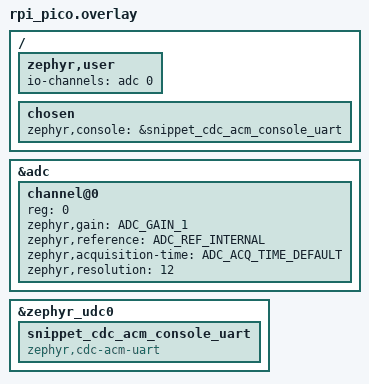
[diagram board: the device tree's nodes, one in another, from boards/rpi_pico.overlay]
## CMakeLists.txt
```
# Copyright (c) 2021-2022 TiaC Systems
# SPDX-License-Identifier: Apache-2.0

cmake_minimum_required(VERSION 3.20.0)

# Standard Bridle application boilerplate, includes Zephyr.
find_package(Bridle REQUIRED HINTS $ENV{BRIDLE_BASE})
project("picoclock" VERSION 1.0)
include_directories(inc/)
target_sources(app PRIVATE src/main.c src/display.c src/temp.c src/led.c src/rtc.c src/temp.c src/menu.c src/io.c)
```

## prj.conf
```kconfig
CONFIG_GPIO=y
CONFIG_DISPLAY=y
CONFIG_HEAP_MEM_POOL_SIZE=16384
CONFIG_LOG=y
CONFIG_RTC=y
CONFIG_RTC_UPDATE=y
CONFIG_RTC_ALARM=y
CONFIG_I2C=y
CONFIG_SENSOR=y
CONFIG_ADC=y
```

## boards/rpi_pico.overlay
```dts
/*
 * SPDX-License-Identifier: Apache-2.0
 *
 * Copyright (c) 2022 TOKITA Hiroshi <tokita.hiroshi@fujitsu.com>
 */

/ {
	zephyr,user {
		io-channels = <&adc 0>;
	};
	chosen {
			zephyr,console = &snippet_cdc_acm_console_uart;
		};
	        
		
};

&adc {
	#address-cells = <1>;
	#size-cells = <0>;

	channel@0 {
		reg = <0>;
		zephyr,gain = "ADC_GAIN_1";
		zephyr,reference = "ADC_REF_INTERNAL";
		zephyr,acquisition-time = <ADC_ACQ_TIME_DEFAULT>;
		zephyr,resolution = <12>;
	};
};

/*
 * Copyright (c) 2023 TiaC Systems
 * SPDX-License-Identifier: Apache-2.0
 */



&zephyr_udc0 {
	snippet_cdc_acm_console_uart: snippet_cdc_acm_console_uart {
		compatible = "zephyr,cdc-acm-uart";
	};
};
```

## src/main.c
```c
#include <string.h>
#include <zephyr/kernel.h>
#include <zephyr/drivers/display.h>
#include <zephyr/device.h>
#include <zephyr/drivers/rtc.h>
#include <zephyr/drivers/sensor.h>
#include <zephyr/drivers/gpio.h>
#include <zephyr/sys/util.h>
#include <zephyr/drivers/adc.h>

#include "def.h"
#include "display.h"
#include "temp.h"
#include "led.h"
#include "menu.h"
#include "rtc.h"
#include "temp.h"
#include "io.h"

static struct gpio_dt_spec button = GPIO_DT_SPEC_GET(DT_ALIAS(sw0), gpios);
static struct gpio_dt_spec button2 = GPIO_DT_SPEC_GET(DT_ALIAS(sw1), gpios);
static struct gpio_dt_spec button3 = GPIO_DT_SPEC_GET(DT_ALIAS(sw2), gpios);



struct display_capabilities caps;



//basically copied example from zephyr/samples/drivers/adc
//with the rpi_pico.overlay thing because nothing else worked
//in boards/rpi_pico.overlay

const struct adc_dt_spec adc_channel0 = ADC_DT_SPEC_GET(DT_PATH(zephyr_user));

const struct device *dev = DEVICE_DT_GET(DT_CHOSEN(zephyr_display));

const struct device *rtc = DEVICE_DT_GET(DT_NODELABEL(clock_rtc));

const struct device *devtemp = DEVICE_DT_GET(DT_NODELABEL(clock_dts));


//Flags
//from menu.h global bool variables, menu.c sets those variables; main.c and menu.c uses them

int main() {


    gpio_pin_configure_dt(&button, GPIO_INPUT);
    gpio_pin_configure_dt(&button2, GPIO_INPUT);
    gpio_pin_configure_dt(&button3, GPIO_INPUT);
    
    struct rtc_time time;/* = {
        .tm_sec = 0,            //sec
        .tm_min = 47,           //minute
        .tm_hour = 9,          //hour
        .tm_mday = 15,          //day of month
        .tm_mon = 2,            //month
        .tm_year = 2024,        //year
        .tm_wday = 6,           //weekday
        
    };
  
    
    rtc_set_time(rtc,&time);*/
    rtc_get_time(rtc, &time);
    printf("year rtc from main.c: %d\n", time.tm_year);


    display_get_capabilities(dev, &caps);
    display_set_pixel_format(dev, PIXEL_FORMAT_MONO01 );
    
   
    printf("x res: %d\ny res: %d\n",caps.x_resolution, caps.y_resolution);

    clearDisplay(dev);

    //writing stuff
    
    displayChar(dev, POS1, POSY,'0');
    displayChar(dev, POS2, POSY,'1');
    displayChar(dev, POSCOL, POSY,':');
    displayChar(dev, POS3, POSY,2);
    displayChar(dev, POS4, POSY,3);    
    
    int hour = 0;
    int minute = 0;
    int day = 0; 
    int currentPosHr = POS1;
    int currentPosMin = POS3;
    
    clearDisplay(dev);
    
    int prevHr = -1;
    int prevMin = -1;
    int prevDay = -1;
    int returnSwitchTemp = -1;
    int returnSwitchMenu = -1;
    int returnTimeAndDay = -1;
    uint8_t val = 12;
    uint8_t bcd = bin2bcd(val);

/*
    bcd:
    dec to bin: 
    12
    0000 1100
    bcd:
dec: 1    2
    0001 0010

*/

    uint8_t mask = 0b00001111;  
    uint8_t secondDigit = ((bcd >> 0) & mask) + 0x30;    //mask the first ,4bit
    uint8_t firstDigit = ((bcd >> 4) & mask) + 0x30;  //mask the second 4bit and add value to go to the 0-9 values in the ascii table
    

    printf("first digit ascii num: %x char: %c\n", firstDigit,(char)firstDigit);
    printf("second digit ascii num: %x char: %c\n", secondDigit,(char)secondDigit);

    //turn on by default
    //bool toggleAutolight = true; 
    
    while(true){
        //printf("H: %d  M: %d  S: %d  \n",time.tm_hour, time.tm_min, time.tm_sec);
        
        //because of blinkChar() you'll have to wait until this if condition is checked in the while loop
        //just a simple example/test for the button; possible fix with "async interrupt handlers (?)"
        //https://docs.zephyrproject.org/latest/kernel/services/interrupts.html
        //for now press the button longer a bit to trigger the if statements in main() and switchToTemp() 

        //buttons
        int val = gpio_pin_get_dt(&button);
        int val2 = gpio_pin_get_dt(&button2);
        int val3 = gpio_pin_get_dt(&button3);
        //printf("buttonval: %d\n", val);
        if(val != 0){
            
            returnSwitchTemp = switchToTemp(dev,devtemp); //switch to the temperature view and stay there until button is pressed again
            
        }
        if(val2 != 0){
            //scrollText(dev,':');


            //set time and date
            
            returnTimeAndDay = setTimeAndDay(dev,rtc);

        }

        
        if(val3 != 0){
            /*if(toggleAutolight == true){
                toggleAutolight = false;
                setLED(dev, 10, 0);
            }
            else{
                toggleAutolight = true;
                setLED(dev, 10, 1);
                
            }*/
            returnSwitchMenu = switchToMenu(dev);
            

        }
        

        if(f_autolight){
            setLED(dev, 12, 1); //if you change to temp display or clockset display the led goes of because clearLEDs() is called in those functions this turns on the hole time while toggleAutolight is true

            updateAutolight(dev, adc_channel0);
            
        }
        else{
            setLED(dev, 12, 0);
        }
        
        
        if(returnSwitchTemp == 0){
            //if returned from switchToTemp() update/set hours and minutes
            prevHr = -1;
            prevMin = -1; //set to default to simulate "restart"
            prevDay = -1;
            returnSwitchTemp = -1; //set it to -1 or any value to not trigger this statement again
            printf("display reset!\n");
        }
        if(returnSwitchMenu == 0){
            prevHr = -1;
            prevMin = -1;
            prevDay = -1;
            returnSwitchMenu = -1;
            printf("display reset!\n");

        }
        if(returnTimeAndDay == 0){
            prevHr = -1;
            prevMin = -1;
            prevDay = -1;
            returnTimeAndDay = -1;
            printf("display reset!\n");

        }

        
        rtc_get_time(rtc, &time);
        if(f_twelveHourClock == true){
            //activate am/pm func (just turn on/off leds for )
            setLED(dev, 9, 1);
            //maybe
            // https://stackoverflow.com/questions/63976824/how-to-convert-hour-number-from-24h-to-12h-format-without-any-conditional-operat
            if(time.tm_hour < 12){ //from 0-12 in 24h format
                //in the AMs
                setLED(dev, 8, 1); //turn on AM led
                setLED(dev, 9, 0); //turn off PM led

                int hourFormatted = (time.tm_hour % 12); // limit to 12
                if(hourFormatted == 0){
                    hourFormatted = 12; //take care of 0s in 24h format, they dont exist in 12h format
                }
                //printf("hour in 12h format: %d\nnormal hour: %d\n", hourFormatted, time.tm_hour);
                hour = hourFormatted;       
                

                
            }
            if(time.tm_hour > 11){ //from 12-24 in 24h format 
                //in the PMs
                
                setLED(dev, 8, 0); //turn off AM led
                setLED(dev, 9, 1); //turn on PM led
                int hourFormatted = (time.tm_hour % 12); // limit to 12
                if(hourFormatted == 0){ //take care of 0s in 24h format, they dont exist in 12h format
                    hourFormatted = 12;
                }
                //printf("hour in 12h format: %d\nnormal hour: %d\n", hourFormatted, time.tm_hour);
                hour = hourFormatted; //set the main hour variable to the formatted 12h version
                
            }
            
        }
        else if(f_twelveHourClock == false){
            
            setLED(dev, 8, 0);
            setLED(dev, 9, 0);
            hour = time.tm_hour; //dont set main hour variable to the formatted 12h version, keep it as is
        }
        
        minute = time.tm_min; 
        day = time.tm_wday;
        
            

        
        if(hour < 10 && (hour != prevHr)){
            clearChar(dev,currentPosHr,POSY); //clear previous char
            displayChar(dev, currentPosHr, POSY, '0'); //set it to 0 so it doesnt look empty
            currentPosHr = POS2; //update location 
            clearChar(dev,currentPosHr,POSY);
            displayChar(dev, currentPosHr, POSY, hour + '0'); //converting it to a char so it looks up the ascii table 
            prevHr = hour;
            currentPosHr = POS1;

        }
//seperate 2digit int into 2 seperate ints via bcd 
        else if(hour > 9 && (hour != prevHr)){

            uint8_t bcd = bin2bcd(hour);

            uint8_t mask = 0b00001111;
    
            uint8_t secondDigit = ((bcd >> 0) & mask) + 0x30;    //mask the first 4bit
            uint8_t firstDigit = ((bcd >> 4) & mask) + 0x30;  //mask the second 4bit and add value to go to the 0-9 values in the ascii table
            currentPosHr = POS1;
            
            clearChar(dev,POS1,POSY);
            displayChar(dev, POS1, POSY, firstDigit);
            clearChar(dev,POS2, POSY);
            displayChar(dev, POS2, POSY, secondDigit);
            prevHr = hour;

        }

        
        
        if(minute < 10 && (minute != prevMin)){
            clearChar(dev, currentPosMin,POSY); //clear previous char
            displayChar(dev, currentPosMin, POSY, '0'); //set it to 0 so it doesnt look empty


            currentPosMin = POS4; //update location 
            clearChar(dev,currentPosMin,POSY);
            displayChar(dev, currentPosMin, POSY, minute + '0');
            prevMin = minute;
            currentPosMin = POS3;

        }
        else if(minute > 9 && (minute != prevMin)){

            uint8_t bcd = bin2bcd(minute);

            uint8_t mask = 0b00001111;
    
            uint8_t secondDigit = ((bcd >> 0) & mask) + 0x30;    //mask the first 4bit
            uint8_t firstDigit = ((bcd >> 4) & mask) + 0x30;  //mask the second 4bit and add value to go to the 0-9 values in the ascii table            
            currentPosMin = POS3;
            
            clearChar(dev,POS3,POSY);
            displayChar(dev, POS3, POSY, firstDigit);
            clearChar(dev,POS4, POSY);
            displayChar(dev, POS4, POSY, secondDigit);    
            prevMin = minute;
        
        }

        if(day != prevDay){
            updateDay(rtc);
            printf("updating (prev) day   %d %d\n",day, prevDay);
            prevDay = day;
            printf("updating day   %d %d\n",day, prevDay);
        }

        blinkChar(dev, POSCOL, POSY, ':');
        
        /* TEST FOR FLICKERING 
        //flickers everytime on rtc_get_time call
        */
        
        /*while(true){
            rtc_get_time(rtc, &time);
 
        }*/

    }    
    

    printf("Done.\n");
    return 0;
}
```

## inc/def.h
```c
#ifndef DEF_H
#define DEF_H
// defines/constants 

//defines for main positions on the led matrix
#define POS1        0
#define POS2        5
#define POSCOL      9
#define POS3       13
#define POS4       18
#define POSY        0


#endif
```

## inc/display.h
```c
#ifndef DISPLAY_H
#define DISPLAY_H

#include <zephyr/device.h>
// display specific functions 
int displayChar(const struct device *dev, int x, int y, char c);
int clearChar(const struct device *dev, int index, int y);
int clearDisplay(const struct device *dev);
void blinkChar(const struct device *dev, int x, int y, char c);
int dimmDisplay(const struct device *dev, uint8_t brightness);


#endif
```

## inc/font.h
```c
#ifndef FONT_H
#define FONT_H

//FONT[1][2]: 
//      1 = total elements
//      2 = lines inside elements
const unsigned char FONT[128][7] = {
    //values in binary because easier to read
    //ascii values, empty if none used
    { /* ascii_0 */ },
    { /* ascii_1 */ },
    { /* ascii_2 */ },
    { /* ascii_3 */ },
    { /* ascii_4 */ },
    { /* ascii_5 */ },
    { /* ascii_6 */ },
    { /* ascii_7 */ },
    { /* ascii_8 */ },
    { /* ascii_9 */ },
    { /* ascii_10 */ },
    { /* ascii_11 */ },
    { /* ascii_12 */ },
    { /* ascii_13 */ },
    { /* ascii_14 */ },
    { /* ascii_15 */ },
    { /* ascii_16 */ },
    { /* ascii_17 */ },
    { /* ascii_18 */ },
    { /* ascii_19 */ },
    { /* ascii_20 */ },
    { /* ascii_21 */ },
    { /* ascii_22 */ },
    { /* ascii_23 */ },
    { /* ascii_24 */ },
    { /* ascii_25 */ },
    { /* ascii_26 */ },
    { /* ascii_27 */ },
    { /* ascii_28 */ },
    { /* ascii_29 */ },
    { /* ascii_30 */ },
    { /* ascii_31 */ },
    { /* ascii_32 */ },
    { /* ascii_33 */ },
    { /* ascii_34 */ },
    { /* ascii_35 */ },
    { /* ascii_36 */ },
    { /* ascii_37 */ },
    { /* ascii_38 */ },
    { /* ascii_39 */ },
    { /* ascii_40 */ },
    { /* ascii_41 */ },
    { /* ascii_42 */ },
    { /* ascii_43 */ },
    { /* ascii_44 */ },
    { /* ascii_45 */ },
    { /* acsii_46, hex:  0x2e, char: '.' */ 
        
        0b00000000,
        0b00000000,
        0b00000000,
        0b00000000,
        0b00000000,
        0b00000110,
        0b00000110
    },
    { /* ascii_47 */ },
    { /* acsii_48, hex: 0x30, char: '0' */ 
        0b00000110,
        0b00001001,
        0b00001001,
        0b00001001,
        0b00001001,
        0b00001001,
        0b00000110
    },
    { /* acsii_49, hex: 0x31, char: '1' */ 
        0b00000010,
        0b00000110,
        0b00001010,
        0b00000010,
        0b00000010,
        0b00000010,
        0b00000010
    },
    { /* acsii_50, hex: 0x32, char: '2' */ 
        0b00000110,
        0b00001001,
        0b00000001,
        0b00000010,
        0b00000100,
        0b00001000,
        0b00001111
    },
    { /* acsii_51, hex: 0x33, char: '3' */
        0b00000110,
        0b00001001,
        0b00000001,
        0b00000110,
        0b00000001,
        0b00001001,
        0b00000110
    },
    { /* acsii_52, hex: 0x34, char: '4' */ 
        0b00000001,
        0b00000011,
        0b00000101,
        0b00001001,
        0b00001111,
        0b00000001,
        0b00000001
    },
    { /* acsii_53, hex: 0x35, char: '5' */ 
        0b00001111,
        0b00001000,
        0b00001110,
        0b00000001,
        0b00000001,
        0b00001001,
        0b00000110
    },
    { /* acsii_54, hex: 0x36, char: '6' */ 
        0b00000010,
        0b00000100,
        0b00001000,
        0b00001110,
        0b00001001,
        0b00001001,
        0b00000110
    },
    { /* acsii_55, hex: 0x37, char: '7' */ 
        0b00001111,
        0b00001001,
        0b00000001,
        0b00000010,
        0b00000010,
        0b00000010,
        0b00000010
        
    },
    { /* acsii_56, hex: 0x38, char: '8' */ 
        0b00000110,
        0b00001001,
        0b00001001,
        0b00000110,
        0b00001001,
        0b00001001,
        0b00000110
    },
    { /* acsii_57, hex: 0x39, char: '9' */ 
        0b00000110,
        0b00001001,
        0b00001001,
        0b00000111,
        0b00000001,
        0b00000010,
        0b00000100
    },
    {  /* acsii_58, hex: 0x3a, char: ':' */ 
        0b00000000,         //........
        0b00000110,         //.....11.
        0b00000110,         //.....11.
        0b00000000,         //........
        0b00000110,         //.....11.
        0b00000110,         //.....11.
        0b00000000          //........
    },
    { /* ascii_59 */ },
    { /* ascii_60 */ },
    { /* ascii_61 */ },
    { /* ascii_62 */ },
    { /* ascii_63 */ },
    { /* ascii_64 */ },
    { /* acsii_65, hex: 0x41, char: 'A' */
        0b00000110,         //.....11.
        0b00001001,         //....1..1
        0b00001001,         //....1..1
        0b00001111,         //....1111
        0b00001001,         //....1..1
        0b00001001,         //....1..1
        0b00001001 
    },
    { /* acsii_66, hex: 0x42, char: 'B' */ 
        0b00001110,       //....111.
        0b00001001,       //....1..1
        0b00001001,       //....1..1
        0b00001110,       //....111.
        0b00001001,       //....1..1
        0b00001001,       //....1..1
        0b00001110        //....111. 
    },
    { /* acsii_67, hex: 0x43, char: 'C' */ 
        0b00000110,       //.....11.
        0b00001001,       //....1..1
        0b00001000,       //....1...
        0b00001000,       //....1...
        0b00001000,       //....1...
        0b00001001,       //....1..1
        0b00000110        //.....11. 
    },
    { /* acsii_68, hex: 0x44, char: 'D' */ 
        0b00001110,     //....111.
        0b00001001,     //....1..1
        0b00001001,     //....1..1
        0b00001001,     //....1..1
        0b00001001,     //....1..1
        0b00001001,     //....1..1
        0b00001110      //....111. 
    },
    { /* acsii_69, hex: 0x45, char: 'E' */ 
        0b00001111,     //....1111
        0b00001000,     //....1...
        0b00001000,     //....1...
        0b00001111,     //....1111
        0b00001000,     //....1...
        0b00001000,     //....1...
        0b00001111      //....1111
    },
    { /* acsii_70, hex: 0x46, char: 'F' */ 
        0b00001111,     //....1111
        0b00001000,     //....1...
        0b00001000,     //....1...
        0b00001111,     //....1111
        0b00001000,     //....1...
        0b00001000,     //....1...
        0b00001000      //....1... 
    },
    { /* ascii_71 */ },
    { /* ascii_72 */ },
    { /* ascii_73 */ },
    { /* ascii_74 */ },
    { /* ascii_75 */ },
    { /* ascii_76, hex: 0x4c, char: L */ 
        0b00001000,
        0b00001000,
        0b00001000,
        0b00001000,
        0b00001000,
        0b00001000,
        0b00001111
    },
    { /* ascii_77 */ },
    { /* ascii_78, hex: 0x4e, char: N */ 
        0b00001001,
        0b00001001,
        0b00001101,
        0b00001011,
        0b00001001,
        0b00001001,
        0b00001001
    },
    { /* ascii_79, hex: 0x4f, char: O */ 
        0b00000110,
        0b00001001,
        0b00001001,
        0b00001001,
        0b00001001,
        0b00001001,
        0b00000110
    },
    { /* ascii_80 */ },
    { /* ascii_81 */ },
    { /* ascii_82 */ },
    { /* ascii_83 */ },
    { /* ascii_84 */ },
    { /* ascii_85 */ },
    { /* ascii_86 */ },
    { /* ascii_87 */ },
    { /* ascii_88 */ },
    { /* ascii_89 */ },
    { /* ascii_90 */ },
    { /* ascii_91 */ },
    { /* ascii_92 */ },
    { /* ascii_93 */ },
    { /* ascii_94 */ },
    { /* ascii_95 */ },
    { /* ascii_96 */ },
    { /* ascii_97 */ },
    { /* ascii_98 */ },
    { /* ascii_99 */ },
    { /* ascii_100 */ },
    { /* ascii_101 */ },
    { /* ascii_102 */ },
    { /* ascii_103 */ },
    { /* ascii_104 */ },
    { /* ascii_105 */ },
    { /* ascii_106 */ },
    { /* ascii_107 */ },
    { /* ascii_108 */ },
    { /* ascii_109 */ },
    { /* ascii_110 */ },
    { /* ascii_111 */ },
    { /* ascii_112 */ },
    { /* ascii_113 */ },
    { /* ascii_114 */ },
    { /* ascii_115 */ },
    { /* ascii_116 */ },
    { /* ascii_117 */ },
    { /* ascii_118 */ },
    { /* ascii_119 */ },
    { /* ascii_120 */ },
    { /* ascii_121 */ },
    { /* ascii_122 */ },
    { /* ascii_123 */ },
    { /* ascii_124 */ },
    { /* ascii_125 */ },
    { /* ascii_126 */ },
    { /* ascii_127 */ }
    
};
#endif
```

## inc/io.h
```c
#ifndef IO_H
#define IO_H
#include <zephyr/device.h>
#include <zephyr/drivers/adc.h>
//functions for I/O on the board (LDR, Buzzer etc...)
void updateAutolight(const struct device *dev, const struct adc_dt_spec adc);

#endif
```

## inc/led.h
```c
#ifndef LED_H
#define LED_H
#include <zephyr/device.h>
//functions for status leds


void setLED(const struct device *dev, int number, int state);
void clearLEDs (const struct device *dev);


#endif
```

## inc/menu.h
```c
#ifndef MENU_H
#define MENU_H
#include <zephyr/device.h>
#include <stdbool.h>
//functions that change the whole screen aka switch to specified menus
int switchToMenu(const struct device *dev);
int switchToTemp(const struct device *display_device, const struct device *temp_device);
int switchToDate(const struct device *dev, const struct device *rtc);


//flags
//Flags
extern bool f_autolight;
extern bool f_twelveHourClock;

#endif
```

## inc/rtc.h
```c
#ifndef RTC_H
#define RTC_H
#include <zephyr/device.h>
//rtc functions 

void updateDay(const struct device *rtc);

int setTimeAndDay(const struct device *dev, const struct device *rtc);

#endif
```

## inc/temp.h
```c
#ifndef TEMP_H
#define TEMP_H
#include <zephyr/device.h>

//functions for temp readings

void updateTemp(const struct device *dev);



#endif
```

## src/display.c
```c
#include <stdio.h>
#include <zephyr/device.h>
#include <zephyr/drivers/display.h>
#include <zephyr/kernel.h>
#include <string.h>

#include "display.h"
#include "font.h"

int clearChar(const struct device *dev, int index, int y){
    uint8_t charbuf[7] = { };
    memset(charbuf, 0b00000000, sizeof(charbuf));
    struct display_buffer_descriptor char_buf_desc = {
        .buf_size = sizeof(charbuf),
        .width = 4,
        .height = 7,
        .pitch = 4,
    };
    int ret = display_write(dev, index, y, &char_buf_desc, charbuf);
    if(ret != 0){
        printf("display_write failed\n");
        
        return -1;
    }
    else{
        return 0;
    }
    
}

int clearDisplay(const struct device *dev){

    int x = 22;
    int y = 7;

    uint8_t dispbuf[22] = { };

    struct display_buffer_descriptor disp_buf_desc = {

        .buf_size = sizeof(dispbuf),
        .width = x,
        .height = y,
        .pitch = x,
    };
    memset(dispbuf, 0b00000000, sizeof(dispbuf)); 
     //clear the screen use whole-screen buffer
    int ret = display_write(dev, 0, 0, &disp_buf_desc, dispbuf);
    if(ret != 0){
        printf("display_write failed\n");
        return -1;
    }
    else{
        return 0;
    }
}

int displayChar(const struct device *dev, int x, int y, char c) {
    
    uint8_t index = c;

    uint8_t charbuf[7] = { };
    memset(charbuf, 0b00000000, sizeof(charbuf));
    struct display_buffer_descriptor char_buf_desc = {
        .buf_size = sizeof(charbuf),
        .width =  4,
        .height = 7,
        .pitch =  4,
    };

    //display chars use char buffer
            
    //shift 4bits to the left and use the right 4 bits as the second character
    //    0000 0110 <- normal values 
    //    0000 1001 
    //
    //    0110 0000 <- shifted 4 bits to the left
    //    bitwise OR ( | ) with the non shifted next value
    //    0110 0000
    //    0000 1001
    //    ---------
    //    0110 1001
    // 1. line|2. line (it's probably way too complicated than it should be)

    int indexFirstLine = 0;
    int indexSecondLine = 1;
    for(int i = 0; i < sizeof(charbuf); i++){
        unsigned char firstLine = FONT[index][indexFirstLine];
        unsigned char secondLine = FONT[index][indexSecondLine];
        unsigned char mergedLine = firstLine << 4 | secondLine; //shift first 4 places to the left and merge shifted first and non-shifted second
        charbuf[i] = mergedLine;
        indexFirstLine += 2; //count to the second next line, skip the next because it was merged from secondLine already 
        if(indexSecondLine == (sizeof(charbuf) - 1)){
            indexSecondLine++;  //if at end of array only get next line otherwise ==> array out of bounce 
        }
        else{
            indexSecondLine += 2;
        }
    }

    int ret = display_write(dev, x, y, &char_buf_desc, charbuf); //display buffer

    if(ret != 0){
        printf("display_write failed\n"); 
    }

    return 0;

    
}
void blinkChar(const struct device *dev, int x, int y, char c){
        //blinking colon
        displayChar(dev, x, y, c);
        k_msleep(500);
        clearChar(dev, x, y);      
        k_msleep(500);

}
int dimmDisplay(const struct device *dev, uint8_t brightness){
    return display_set_brightness(dev,brightness);
    
}
```

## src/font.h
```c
#ifndef FONT_H
#define FONT_H

//FONT[1][2]: 
//      1 = total elements
//      2 = lines inside elements
const unsigned char FONT[128][7] = {
    //values in binary because easier to read
    //ascii values, empty if none used
    { /* ascii_0 */ },
    { /* ascii_1 */ },
    { /* ascii_2 */ },
    { /* ascii_3 */ },
    { /* ascii_4 */ },
    { /* ascii_5 */ },
    { /* ascii_6 */ },
    { /* ascii_7 */ },
    { /* ascii_8 */ },
    { /* ascii_9 */ },
    { /* ascii_10 */ },
    { /* ascii_11 */ },
    { /* ascii_12 */ },
    { /* ascii_13 */ },
    { /* ascii_14 */ },
    { /* ascii_15 */ },
    { /* ascii_16 */ },
    { /* ascii_17 */ },
    { /* ascii_18 */ },
    { /* ascii_19 */ },
    { /* ascii_20 */ },
    { /* ascii_21 */ },
    { /* ascii_22 */ },
    { /* ascii_23 */ },
    { /* ascii_24 */ },
    { /* ascii_25 */ },
    { /* ascii_26 */ },
    { /* ascii_27 */ },
    { /* ascii_28 */ },
    { /* ascii_29 */ },
    { /* ascii_30 */ },
    { /* ascii_31 */ },
    { /* ascii_32 */ },
    { /* ascii_33 */ },
    { /* ascii_34 */ },
    { /* ascii_35 */ },
    { /* ascii_36 */ },
    { /* ascii_37 */ },
    { /* ascii_38 */ },
    { /* ascii_39 */ },
    { /* ascii_40 */ },
    { /* ascii_41 */ },
    { /* ascii_42 */ },
    { /* ascii_43 */ },
    { /* ascii_44 */ },
    { /* ascii_45 */ },
    { /* acsii_46, hex:  0x2e, char: '.' */ 
        
        0b00000000,
        0b00000000,
        0b00000000,
        0b00000000,
        0b00000000,
        0b00000110,
        0b00000110
    },
    { /* ascii_47 */ },
    { /* acsii_48, hex: 0x30, char: '0' */ 
        0b00000110,
        0b00001001,
        0b00001001,
        0b00001001,
        0b00001001,
        0b00001001,
        0b00000110
    },
    { /* acsii_49, hex: 0x31, char: '1' */ 
        0b00000010,
        0b00000110,
        0b00001010,
        0b00000010,
        0b00000010,
        0b00000010,
        0b00000010
    },
    { /* acsii_50, hex: 0x32, char: '2' */ 
        0b00000110,
        0b00001001,
        0b00000001,
        0b00000010,
        0b00000100,
        0b00001000,
        0b00001111
    },
    { /* acsii_51, hex: 0x33, char: '3' */
        0b00000110,
        0b00001001,
        0b00000001,
        0b00000110,
        0b00000001,
        0b00001001,
        0b00000110
    },
    { /* acsii_52, hex: 0x34, char: '4' */ 
        0b00000001,
        0b00000011,
        0b00000101,
        0b00001001,
        0b00001111,
        0b00000001,
        0b00000001
    },
    { /* acsii_53, hex: 0x35, char: '5' */ 
        0b00001111,
        0b00001000,
        0b00001110,
        0b00000001,
        0b00000001,
        0b00001001,
        0b00000110
    },
    { /* acsii_54, hex: 0x36, char: '6' */ 
        0b00000010,
        0b00000100,
        0b00001000,
        0b00001110,
        0b00001001,
        0b00001001,
        0b00000110
    },
    { /* acsii_55, hex: 0x37, char: '7' */ 
        0b00001111,
        0b00001001,
        0b00000001,
        0b00000010,
        0b00000010,
        0b00000010,
        0b00000010
        
    },
    { /* acsii_56, hex: 0x38, char: '8' */ 
        0b00000110,
        0b00001001,
        0b00001001,
        0b00000110,
        0b00001001,
        0b00001001,
        0b00000110
    },
    { /* acsii_57, hex: 0x39, char: '9' */ 
        0b00000110,
        0b00001001,
        0b00001001,
        0b00000111,
        0b00000001,
        0b00000010,
        0b00000100
    },
    {  /* acsii_58, hex: 0x3a, char: ':' */ 
        0b00000000,         //........
        0b00000110,         //.....11.
        0b00000110,         //.....11.
        0b00000000,         //........
        0b00000110,         //.....11.
        0b00000110,         //.....11.
        0b00000000          //........
    },
    { /* ascii_59 */ },
    { /* ascii_60 */ },
    { /* ascii_61 */ },
    { /* ascii_62 */ },
    { /* ascii_63 */ },
    { /* ascii_64 */ },
    { /* acsii_65, hex: 0x41, char: 'A' */
        0b00000110,         //.....11.
        0b00001001,         //....1..1
        0b00001001,         //....1..1
        0b00001111,         //....1111
        0b00001001,         //....1..1
        0b00001001,         //....1..1
        0b00001001 
    },
    { /* acsii_66, hex: 0x42, char: 'B' */ 
        0b00001110,       //....111.
        0b00001001,       //....1..1
        0b00001001,       //....1..1
        0b00001110,       //....111.
        0b00001001,       //....1..1
        0b00001001,       //....1..1
        0b00001110        //....111. 
    },
    { /* acsii_67, hex: 0x43, char: 'C' */ 
        0b00000110,       //.....11.
        0b00001001,       //....1..1
        0b00001000,       //....1...
        0b00001000,       //....1...
        0b00001000,       //....1...
        0b00001001,       //....1..1
        0b00000110        //.....11. 
    },
    { /* acsii_68, hex: 0x44, char: 'D' */ 
        0b00001110,     //....111.
        0b00001001,     //....1..1
        0b00001001,     //....1..1
        0b00001001,     //....1..1
        0b00001001,     //....1..1
        0b00001001,     //....1..1
        0b00001110      //....111. 
    },
    { /* acsii_69, hex: 0x45, char: 'E' */ 
        0b00001111,     //....1111
        0b00001000,     //....1...
        0b00001000,     //....1...
        0b00001111,     //....1111
        0b00001000,     //....1...
        0b00001000,     //....1...
        0b00001111      //....1111
    },
    { /* acsii_70, hex: 0x46, char: 'F' */ 
        0b00001111,     //....1111
        0b00001000,     //....1...
        0b00001000,     //....1...
        0b00001111,     //....1111
        0b00001000,     //....1...
        0b00001000,     //....1...
        0b00001000      //....1... 
    },
    { /* ascii_71 */ },
    { /* ascii_72 */ },
    { /* ascii_73 */ },
    { /* ascii_74 */ },
    { /* ascii_75 */ },
    { /* ascii_76 */ },
    { /* ascii_77 */ },
    { /* ascii_78 */ },
    { /* ascii_79 */ },
    { /* ascii_80 */ },
    { /* ascii_81 */ },
    { /* ascii_82 */ },
    { /* ascii_83 */ },
    { /* ascii_84 */ },
    { /* ascii_85 */ },
    { /* ascii_86 */ },
    { /* ascii_87 */ },
    { /* ascii_88 */ },
    { /* ascii_89 */ },
    { /* ascii_90 */ },
    { /* ascii_91 */ },
    { /* ascii_92 */ },
    { /* ascii_93 */ },
    { /* ascii_94 */ },
    { /* ascii_95 */ },
    { /* ascii_96 */ },
    { /* ascii_97 */ },
    { /* ascii_98 */ },
    { /* ascii_99 */ },
    { /* ascii_100 */ },
    { /* ascii_101 */ },
    { /* ascii_102 */ },
    { /* ascii_103 */ },
    { /* ascii_104 */ },
    { /* ascii_105 */ },
    { /* ascii_106 */ },
    { /* ascii_107 */ },
    { /* ascii_108 */ },
    { /* ascii_109 */ },
    { /* ascii_110 */ },
    { /* ascii_111 */ },
    { /* ascii_112 */ },
    { /* ascii_113 */ },
    { /* ascii_114 */ },
    { /* ascii_115 */ },
    { /* ascii_116 */ },
    { /* ascii_117 */ },
    { /* ascii_118 */ },
    { /* ascii_119 */ },
    { /* ascii_120 */ },
    { /* ascii_121 */ },
    { /* ascii_122 */ },
    { /* ascii_123 */ },
    { /* ascii_124 */ },
    { /* ascii_125 */ },
    { /* ascii_126 */ },
    { /* ascii_127 */ }
    
};
#endif
```

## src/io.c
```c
#include <zephyr/device.h>
#include <zephyr/drivers/adc.h>
#include "display.h"
#include "io.h"


void updateAutolight(const struct device *dev, const struct adc_dt_spec adc){

	uint16_t buf;
	struct adc_sequence sequence = {
		.buffer = &buf,
		/* buffer size in bytes, not number of samples */
		.buffer_size = sizeof(buf),
	};


	adc_channel_setup_dt(&adc);
	

		
	int32_t val_mv; //in mili Volts
	adc_sequence_init_dt(&adc, &sequence);
	int err = adc_read_dt(&adc, &sequence);
	if (err < 0) {
		printk("Could not read (%d)\n", err);
    		
	}
	/*
	 * If using differential mode, the 16 bit value
	 * in the ADC sample buffer should be a signed 2's
	 * complement value.
	 */
	if (adc.channel_cfg.differential) {
		val_mv = (int32_t)((int16_t)buf);
	} 
	else {
		val_mv = (int32_t)buf;
	}
	
	adc_raw_to_millivolts_dt(&adc, &val_mv);
	/* conversion to mV may not be supported, skip if not */
    //printf("current mV: %d\n",val_mv);

    //if over 1500mV is reached dimm the display
    if(val_mv < 1700){ //bright
        dimmDisplay(dev, 100);
    }
    else if(val_mv > 1700){ //dark
        dimmDisplay(dev, 1);
    }
    
}
```

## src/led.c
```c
#include "led.h"
#include <zephyr/drivers/gpio.h>


void clearLEDs(const struct device *dev){
    setLED(dev,1,0);    
    setLED(dev,2,0);    
    setLED(dev,3,0); 
    setLED(dev,4,0); 
    setLED(dev,5,0); 
    setLED(dev,6,0); 
    setLED(dev,7,0); 
    setLED(dev,8,0); 
    setLED(dev,9,0); 
    setLED(dev,10,0); 
    setLED(dev,11,0); 
    setLED(dev,12,0); 
    setLED(dev,13,0); 
    setLED(dev,14,0); 
    setLED(dev,15,0); 
    setLED(dev,16,0); 
    setLED(dev,17,0); 
    setLED(dev,18,0); 
    setLED(dev,19,0); 
}

void setLED(const struct device *dev, int number, int state){

    switch(number){
        
        
        case 1:
        
            struct gpio_dt_spec led1 = GPIO_DT_SPEC_GET(DT_ALIAS(led1),gpios);
            gpio_pin_configure_dt(&led1, GPIO_OUTPUT);
            gpio_pin_set_dt(&led1, state);
            break;
        case 2:
            struct gpio_dt_spec led0 = GPIO_DT_SPEC_GET(DT_ALIAS(led0),gpios);
            gpio_pin_configure_dt(&led0, GPIO_OUTPUT);
            gpio_pin_set_dt(&led0, state);
            break;
        case 3:

            struct gpio_dt_spec led16 = GPIO_DT_SPEC_GET(DT_ALIAS(led16),gpios);
            struct gpio_dt_spec led17 = GPIO_DT_SPEC_GET(DT_ALIAS(led17),gpios);
            gpio_pin_configure_dt(&led16, GPIO_OUTPUT);
            gpio_pin_configure_dt(&led17, GPIO_OUTPUT);
            gpio_pin_set_dt(&led16, state);
            gpio_pin_set_dt(&led17, state);
            break;
        case 4:
            struct gpio_dt_spec led18 = GPIO_DT_SPEC_GET(DT_ALIAS(led18),gpios);
            struct gpio_dt_spec led19 = GPIO_DT_SPEC_GET(DT_ALIAS(led19),gpios);
            gpio_pin_configure_dt(&led18, GPIO_OUTPUT);
            gpio_pin_configure_dt(&led19, GPIO_OUTPUT);
            gpio_pin_set_dt(&led18, state);
            gpio_pin_set_dt(&led19, state);
            break;
        case 5:
            struct gpio_dt_spec led20 = GPIO_DT_SPEC_GET(DT_ALIAS(led20),gpios);
            struct gpio_dt_spec led21 = GPIO_DT_SPEC_GET(DT_ALIAS(led21),gpios);
            gpio_pin_configure_dt(&led20, GPIO_OUTPUT);
            gpio_pin_configure_dt(&led21, GPIO_OUTPUT);
            gpio_pin_set_dt(&led20, state);
            gpio_pin_set_dt(&led21, state);
            break;
        case 6:
            struct gpio_dt_spec led22 = GPIO_DT_SPEC_GET(DT_ALIAS(led22),gpios);
            gpio_pin_configure_dt(&led22, GPIO_OUTPUT);
            gpio_pin_set_dt(&led22, state);
            break;
        case 7:
            struct gpio_dt_spec led23 = GPIO_DT_SPEC_GET(DT_ALIAS(led23),gpios);
            gpio_pin_configure_dt(&led23, GPIO_OUTPUT);
            gpio_pin_set_dt(&led23, state);
            break;

        case 8:
            struct gpio_dt_spec led24 = GPIO_DT_SPEC_GET(DT_ALIAS(led24),gpios);
            gpio_pin_configure_dt(&led24, GPIO_OUTPUT);
            gpio_pin_set_dt(&led24, state);
            break;
        case 9:
            struct gpio_dt_spec led25 = GPIO_DT_SPEC_GET(DT_ALIAS(led25),gpios);
            gpio_pin_configure_dt(&led25, GPIO_OUTPUT);
            gpio_pin_set_dt(&led25, state);
            break;
        case 10:
            struct gpio_dt_spec led26 = GPIO_DT_SPEC_GET(DT_ALIAS(led26),gpios);
            struct gpio_dt_spec led27 = GPIO_DT_SPEC_GET(DT_ALIAS(led27),gpios);
            gpio_pin_configure_dt(&led26, GPIO_OUTPUT);
            gpio_pin_configure_dt(&led27, GPIO_OUTPUT);
            gpio_pin_set_dt(&led26, state);   
            gpio_pin_set_dt(&led27, state);   
            break;
        case 11:
            struct gpio_dt_spec led28 = GPIO_DT_SPEC_GET(DT_ALIAS(led28),gpios);
            struct gpio_dt_spec led29 = GPIO_DT_SPEC_GET(DT_ALIAS(led29),gpios);
            gpio_pin_configure_dt(&led28, GPIO_OUTPUT);
            gpio_pin_configure_dt(&led29, GPIO_OUTPUT);
            gpio_pin_set_dt(&led28, state);
            gpio_pin_set_dt(&led29, state);
            break;
        case 12:
            struct gpio_dt_spec led30 = GPIO_DT_SPEC_GET(DT_ALIAS(led30),gpios);
            struct gpio_dt_spec led31 = GPIO_DT_SPEC_GET(DT_ALIAS(led31),gpios);
            gpio_pin_configure_dt(&led30, GPIO_OUTPUT);
            gpio_pin_configure_dt(&led31, GPIO_OUTPUT);
            gpio_pin_set_dt(&led30, state);
            gpio_pin_set_dt(&led31, state);
            break;
                
    
            //weekdays
        case 13:
            struct gpio_dt_spec led2 = GPIO_DT_SPEC_GET(DT_ALIAS(led2),gpios);
            struct gpio_dt_spec led3 = GPIO_DT_SPEC_GET(DT_ALIAS(led3),gpios);
            gpio_pin_configure_dt(&led2, GPIO_OUTPUT);
            gpio_pin_configure_dt(&led3, GPIO_OUTPUT);
            gpio_pin_set_dt(&led2, state);
            gpio_pin_set_dt(&led3, state);
            break;
        case 14:
            struct gpio_dt_spec led4 = GPIO_DT_SPEC_GET(DT_ALIAS(led4),gpios);
            struct gpio_dt_spec led5 = GPIO_DT_SPEC_GET(DT_ALIAS(led5),gpios);
            gpio_pin_configure_dt(&led4, GPIO_OUTPUT);
            gpio_pin_configure_dt(&led5, GPIO_OUTPUT);
            gpio_pin_set_dt(&led4, state);
            gpio_pin_set_dt(&led5, state);
            break;
        case 15:
            struct gpio_dt_spec led6 = GPIO_DT_SPEC_GET(DT_ALIAS(led6),gpios);
            struct gpio_dt_spec led7 = GPIO_DT_SPEC_GET(DT_ALIAS(led7),gpios);
            gpio_pin_configure_dt(&led6, GPIO_OUTPUT);
            gpio_pin_configure_dt(&led7, GPIO_OUTPUT);
            gpio_pin_set_dt(&led6, state);
            gpio_pin_set_dt(&led7, state);
            break;
        case 16:
            struct gpio_dt_spec led8 = GPIO_DT_SPEC_GET(DT_ALIAS(led8),gpios);
            struct gpio_dt_spec led9 = GPIO_DT_SPEC_GET(DT_ALIAS(led9),gpios);
            gpio_pin_configure_dt(&led8, GPIO_OUTPUT);
            gpio_pin_configure_dt(&led9, GPIO_OUTPUT);
            gpio_pin_set_dt(&led8, state);
            gpio_pin_set_dt(&led9, state);
            break;
        case 17:
            struct gpio_dt_spec led10 = GPIO_DT_SPEC_GET(DT_ALIAS(led10),gpios);
            struct gpio_dt_spec led11 = GPIO_DT_SPEC_GET(DT_ALIAS(led11),gpios);
            gpio_pin_configure_dt(&led10, GPIO_OUTPUT);
            gpio_pin_configure_dt(&led11, GPIO_OUTPUT);
            gpio_pin_set_dt(&led10, state);
            gpio_pin_set_dt(&led11, state);
            break;
        case 18:
            struct gpio_dt_spec led12 = GPIO_DT_SPEC_GET(DT_ALIAS(led12),gpios);
            struct gpio_dt_spec led13 = GPIO_DT_SPEC_GET(DT_ALIAS(led13),gpios);
            gpio_pin_configure_dt(&led12, GPIO_OUTPUT);
            gpio_pin_configure_dt(&led13, GPIO_OUTPUT);
            gpio_pin_set_dt(&led12, state);
            gpio_pin_set_dt(&led13, state);
            break;
        case 19:
            struct gpio_dt_spec led14 = GPIO_DT_SPEC_GET(DT_ALIAS(led14),gpios);
            struct gpio_dt_spec led15 = GPIO_DT_SPEC_GET(DT_ALIAS(led15),gpios);
            gpio_pin_configure_dt(&led14, GPIO_OUTPUT);
            gpio_pin_configure_dt(&led15, GPIO_OUTPUT);
            gpio_pin_set_dt(&led14, state);
            gpio_pin_set_dt(&led15, state);
            break;
        
    } 
    
}
```
